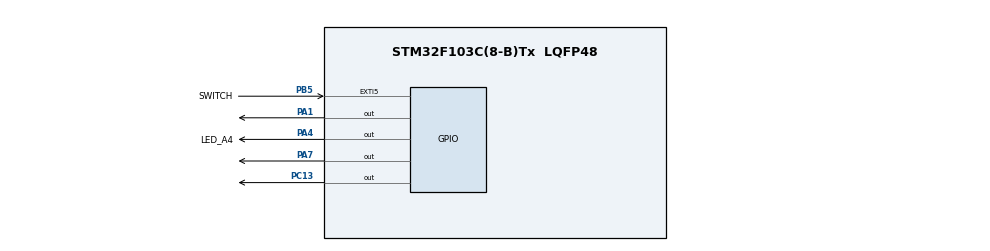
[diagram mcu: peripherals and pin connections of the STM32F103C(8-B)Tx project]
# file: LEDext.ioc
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Mcu.Family=STM32F1
Mcu.Name=STM32F103C(8-B)Tx
Mcu.Package=LQFP48
NVIC.EXTI9_5_IRQn=true\:0\:0\:false\:false\:true\:true\:true\:true
NVIC.PriorityGroup=NVIC_PRIORITYGROUP_4
PA1.PinState=GPIO_PIN_SET
PA1.Signal=GPIO_Output
PA13.Mode=Serial_Wire
PA13.Signal=SYS_JTMS-SWDIO
PA14.Mode=Serial_Wire
PA14.Signal=SYS_JTCK-SWCLK
PA4.GPIO_Label=LED_A4
PA4.Signal=GPIO_Output
PA7.Signal=GPIO_Output
PB5.GPIO_Label=SWITCH
PB5.Signal=GPXTI5
PC13-TAMPER-RTC.Signal=GPIO_Output
PD0-OSC_IN.Mode=HSE-External-Oscillator
PD0-OSC_IN.Signal=RCC_OSC_IN
PD1-OSC_OUT.Mode=HSE-External-Oscillator
PD1-OSC_OUT.Signal=RCC_OSC_OUT
ProjectManager.HeapSize=0x200
ProjectManager.StackSize=0x400
ProjectManager.TargetToolchain=MDK-ARM V5
RCC.APB1Freq_Value=8000000
RCC.APB2Freq_Value=8000000
board=custom

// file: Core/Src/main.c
/* USER CODE BEGIN Header */
/**
  ******************************************************************************
  * @file           : main.c
  * @brief          : Main program body
  ******************************************************************************
  * @attention
  *
  * Copyright (c) 2025 STMicroelectronics.
  * All rights reserved.
  *
  * This software is licensed under terms that can be found in the LICENSE file
  * in the root directory of this software component.
  * If no LICENSE file comes with this software, it is provided AS-IS.
  *
  ******************************************************************************
  */
/* USER CODE END Header */
#include "main.h"
#include "gpio.h"

void SystemClock_Config(void);

/* USER CODE BEGIN 0 */
volatile uint8_t btn_flag = 0;

void HAL_GPIO_EXTI_Callback(uint16_t GPIO_Pin)
{
    if (GPIO_Pin == GPIO_PIN_5)
    {
        // 软件消抖
        static uint32_t last_tick = 0;
        uint32_t now = HAL_GetTick();
        if ((now - last_tick) < 50) return; // 50ms消抖
        last_tick = now;

        // 读取 PB5 电平
        GPIO_PinState state = HAL_GPIO_ReadPin(GPIOB, GPIO_PIN_5);

        // 按键未按下（高电平） → LED 亮
        // 按键按下/拔下线（低电平） → LED 灭
        if (state == GPIO_PIN_SET)
            HAL_GPIO_WritePin(GPIOA, GPIO_PIN_4, GPIO_PIN_SET);   // LED 亮
        else
            HAL_GPIO_WritePin(GPIOA, GPIO_PIN_4, GPIO_PIN_RESET); // LED 灭
    }
}

/* USER CODE END 0 */

/* main.c */
int main(void)
{

  /* MCU Configuration--------------------------------------------------------*/

  /* Reset of all peripherals, Initializes the Flash interface and the Systick. */
  HAL_Init();

  /* Configure the system clock */
  SystemClock_Config();

  /* Initialize all configured peripherals */
  MX_GPIO_Init();

  /* Infinite loop */
  while (1)
  {
        // 读取 PB5 电平，控制 PA4 LED
        if(HAL_GPIO_ReadPin(GPIOB, GPIO_PIN_5) == GPIO_PIN_SET) // 插上 → 高
            HAL_GPIO_WritePin(GPIOA, GPIO_PIN_4, GPIO_PIN_SET);   // LED 亮
        else                                                    // 拔下 → 低
            HAL_GPIO_WritePin(GPIOA, GPIO_PIN_4, GPIO_PIN_RESET); // LED 灭

        HAL_Delay(10); // 10ms 循环
  }
}

void SystemClock_Config(void)
{
  RCC_OscInitTypeDef RCC_OscInitStruct = {0};
  RCC_ClkInitTypeDef RCC_ClkInitStruct = {0};

  /** Initializes the RCC Oscillators according to the specified parameters
  * in the RCC_OscInitTypeDef structure.
  */
  RCC_OscInitStruct.OscillatorType = RCC_OSCILLATORTYPE_HSI;
  RCC_OscInitStruct.HSIState = RCC_HSI_ON;
  RCC_OscInitStruct.HSICalibrationValue = RCC_HSICALIBRATION_DEFAULT;
  RCC_OscInitStruct.PLL.PLLState = RCC_PLL_NONE;
  if (HAL_RCC_OscConfig(&RCC_OscInitStruct) != HAL_OK)
  {
    Error_Handler();
  }

  /** Initializes the CPU, AHB and APB buses clocks
  */
  RCC_ClkInitStruct.ClockType = RCC_CLOCKTYPE_HCLK|RCC_CLOCKTYPE_SYSCLK
                              |RCC_CLOCKTYPE_PCLK1|RCC_CLOCKTYPE_PCLK2;
  RCC_ClkInitStruct.SYSCLKSource = RCC_SYSCLKSOURCE_HSI;
  RCC_ClkInitStruct.AHBCLKDivider = RCC_SYSCLK_DIV1;
  RCC_ClkInitStruct.APB1CLKDivider = RCC_HCLK_DIV1;
  RCC_ClkInitStruct.APB2CLKDivider = RCC_HCLK_DIV1;

  if (HAL_RCC_ClockConfig(&RCC_ClkInitStruct, FLASH_LATENCY_0) != HAL_OK)
  {
    Error_Handler();
  }
}

void Error_Handler(void)
{
  __disable_irq();
  while (1)
  {
  }
}

/**
  * @brief EXTI 中断处理函数
  */

/**
  * @brief 中断回调函数
  */
